# RK3399-AP register map
File version: 1
CPU: CA7 r0p1, little endian, MPU, FPU, I-cache, D-cache, VTOR, 4 interrupt priority bits, 0 interrupts
Registers are 32-bit, read-write, reset 0x0 unless marked. A register's access mark holds for its fields unless they carry their own. Offsets are from the block's base; [hi:lo] are bit positions; <NAME> marks a mode.

## SDMMC
Base 0xFE320000
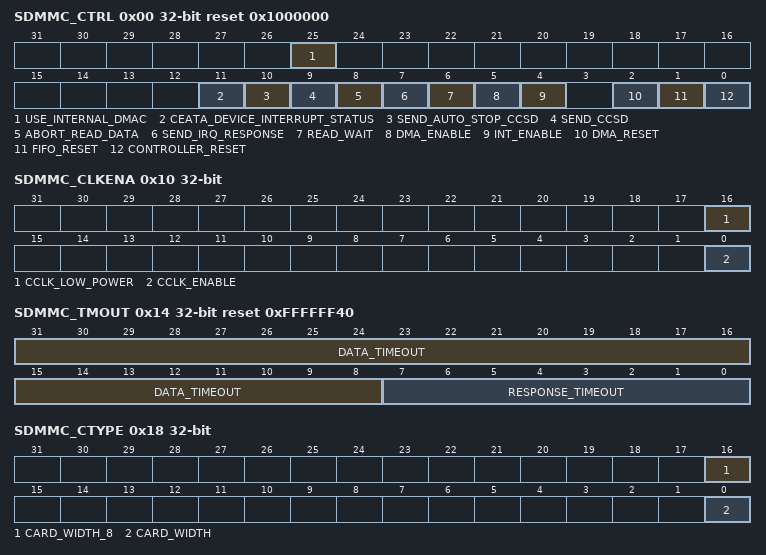
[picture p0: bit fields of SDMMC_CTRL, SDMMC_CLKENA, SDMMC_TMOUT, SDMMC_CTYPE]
0x00 SDMMC_CTRL reset 0x1000000 — Control register
  [25] USE_INTERNAL_DMAC — Present only for the Internal DMAC configuration; else, it is reserved. 0: The host performs data transfers through the slave interface 1: Internal DMAC used for data transfe
  [11] CEATA_DEVICE_INTERRUPT_STATUS — 0: Interrupts not enabled in CE-ATA device (nIEN = 1 in ATA control register) 1: Interrupts are enabled in CE-ATA device (nIEN = 0 in ATA control register) Software should appropriately write to this bit after power-on reset or any other reset to CE-ATA device. After reset, usually CE-ATA device interrupt is disabled (nIEN = 1). If the host enables CE-ATA device interrupt, then software should set this bit.
  [10] SEND_AUTO_STOP_CCSD — 0: Clear bit if Mobile Storage Host Controller does not reset the bit. 1: Send internally generated STOP after sending CCSD to CE-ATA device. NOTE: Always set send_auto_stop_ccsd and send_ccsd bits together send_auto_stop_ccsd should not be set independent of send_ccsd. When set, Mobile Storage Host Controller automatically sends internally- generated STOP command (CMD12) to CE-ATA device. After sending internally-generated STOP command, Auto Command Done (ACD) in RINTSTS is set and generates interrupt to host if Auto Command Done interrupt is not masked. After sending the CCSD, Mobile Storage Host Controller automatically clears send_auto_stop_ccsd bit.
  [9] SEND_CCSD — 0: Clear bit if Mobile Storage Host Controller does not reset the bit. 1: Send Command Completion Signal Disable (CCSD) to CE-ATA device When set, Mobile Storage Host Controller sends CCSD to CE-ATA device. Software sets this bit only if current command is expecting CCS (that is, RW_BLK) and interrupts are enabled in CE-ATA device. Once the CCSD pattern is sent to device, Mobile Storage Host Controller automatically clears send_ccsd bit. It also sets Command Done (CD) bit in RINTSTS register and generates interrupt to host if Command Done interrupt is not masked. NOTE: Once send_ccsd bit is set, it takes two card clock cycles to drive the CCSD on the CMD line. Due to this, during the boundary conditions it may happen that CCSD is sent to the CE-ATA device, even if the device signalled CCS
  [8] ABORT_READ_DATA — 0: no change 1: after suspend command is issued during read-transfer, software polls card to find when suspend happened. Once suspend occurs, software sets bit to reset data state-machine, which is waiting for next block of data. Bit automatically clears once data state machine resets to idle. Used in SDIO card suspend sequence.
  [7] SEND_IRQ_RESPONSE — 0: no change 1: send auto IRQ response Bit automatically clears once response is sent. To wait for MMC card interrupts, host issues CMD40, and SDMMC Controller waits for interrupt response from MMC card(s). In meantime, if host wants SDMMC Controller to exit waiting for interrupt state, it can set this bit, at which time SDMMC Controller command state-machine sends CMD40 response on bus and returns to idle state.
  [6] READ_WAIT — 0: clear read wait 1: assert read wait For sending read-wait to SDIO cards
  [5] DMA_ENABLE — 0: disable DMA transfer mode 1: enable DMA transfer mode Even when DMA mode is enabled, host can still push/pop data into or from FIFO; this should not happen during the normal operation. If there is simultaneous FIFO access from host/DMA, the data coherency is lost. Also, there is no arbitration inside SDMMC Controller to prioritize simultaneous host/DMA access.
  [4] INT_ENABLE — Global interrupt enable/disable bit: 0: disable interrupts 1: enable interrupts The int port is 1 only when this bit is 1 and one or more unmasked interrupts are set.
  [2] DMA_RESET write-1-clears — 0: no change 1: reset internal DMA interface control logic To reset DMA interface, firmware should set bit to 1. This bit is auto-cleared after two AHB clocks.
  [1] FIFO_RESET write-1-clears — 0: no change 1: reset to data FIFO To reset FIFO pointers To reset FIFO, firmware should set bit to 1. This bit is auto- cleared after completion of reset operation
  [0] CONTROLLER_RESET write-1-clears — 0: no change 1: reset SDMMC controller To reset controller, firmware should set bit to 1. This bit is auto- cleared after two AHB and two cclk_in clock cycles. This resets: a. BIU/CIU interface b. CIU and state machines c. abort_read_data, send_irq_response, and read_wait bits of Control register d. start_cmd bit of Command register Does not affect any registers or DMA interface, or FIFO or host interrupts
0x04 SDMMC_PWREN — Power-enable register
  [0] POWER_ENABLE — Power on/off switch for the card. Once power is turned on, firmware should wait for regulator/switch ramp-up time before trying to initialize card. 0: power off 1: power on Bit values output to card_power_en port.
0x08 SDMMC_CLKDIV — Clock-divider register
  [7:0] CLK_DIVIDER0 — Clock divider-0 value. Clock division is 2*n. For example, value of 0 means divide by 2*0 = 0 (no division, bypass), value of 1 means divide by 2*1 = 2, value of "ff"means divide by 2*255 = 510, and so on
0x0C SDMMC_CLKSRC — SD clock source register
  [1:0] CLK_SOURCE — Clock divider source for up to 16 SD cards supported. Each card has two bits assigned to it. For example, bits[1:0] assigned for card-0, which maps and internally routes clock divider[3:0] outputs to cclk_out[15:0] pins, depending on bit value. 00: Clock divider 0 The cclk_out is always from clock divider 0, and this register is not implemented.
0x10 SDMMC_CLKENA — Clock-enable register
  [16] CCLK_LOW_POWER — Low-power control for SD card clock and MMC card clock supported. 0: non-low-power mode 1: low-power mode; stop clock when card in IDLE (should be normally set to only MMC and SD memory cards; for SDIO cards, if interrupts must be detected, clock should not be stopped).
  [0] CCLK_ENABLE — Clock-enable control for SD card clock and MMC card clock supported. 0: clock disabled 1: clock enabled
0x14 SDMMC_TMOUT reset 0xFFFFFF40 — Time-out register
  [31:8] DATA_TIMEOUT — Value for card Data Read Timeout; same value also used for Data Starvation by Host timeout. Value is in number of card output clocks cclk_out of selected card. Note: The software timer should be used if the timeout value is in the order of 100 ms. In this case, read data timeout interrupt needs to be disabled.
  [7:0] RESPONSE_TIMEOUT — Response timeout value. Value is in number of card output clocks –cclk_out.
0x18 SDMMC_CTYPE — Card-type register
  [16] CARD_WIDTH_8 — Indicates if card is 8-bit: 0: non 8-bit mode 1: 8-bit mode
  [0] CARD_WIDTH — Indicates if card is 1-bit or 4-bit: 0: 1-bit mode 1: 4-bit mode
0x1C SDMMC_BLKSIZ reset 0x200 — Block-size register
  [15:0] BLOCK_SIZE
0x20 SDMMC_BYTCNT reset 0x200 — Byte-count register
  [31:0] BYTE_COUNT — Number of bytes to be transferred; should be integer multiple of Block Size for block transfers. For undefined number of byte transfers, byte count should be set to 0. When byte count is set to 0, it is responsibility of host to explicitly send stop/abort command to terminate data transfer.
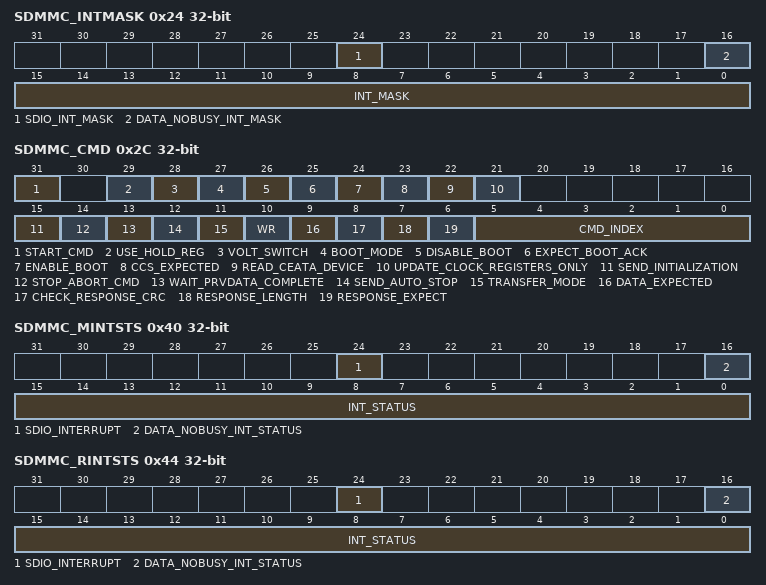
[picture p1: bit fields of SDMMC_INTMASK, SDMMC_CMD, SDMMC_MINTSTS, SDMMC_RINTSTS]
0x24 SDMMC_INTMASK — Interrupt-mask register
  [24] SDIO_INT_MASK — Mask SDIO interrupts. When masked, SDIO interrupt detection for that card is disabled. A 0 masks an interrupt, and 1 enables an interrupt.
  [16] DATA_NOBUSY_INT_MASK — 0: data no busy interrupt not masked 1: data no busy interrupt masked
  [15:0] INT_MASK — Bits used to mask unwanted interrupts. Value of 0 masks interrupt; value of 1 enables interrupt. [15]: End-bit error (read)/Write no CRC (EBE) [14]: Auto command done (ACD) [13]: Start-bit error (SBE) [12]: Hardware locked write error (HLE) [11]: FIFO underrun/overrun error (FRUN) [10]: Data starvation-by-host timeout (HTO) /Volt_switch_int [9]: Data read timeout (DRTO) [8]: Response timeout (RTO) [7]: Data CRC error (DCRC) [6]: Response CRC error (RCRC) [5]: Receive FIFO data request (RXDR) [4]: Transmit FIFO data request (TXDR) [3]: Data transfer over (DTO) [2]: Command done (CD) [1]: Response error (RE) [0]: Card detect (CD)
0x28 SDMMC_CMDARG — Command-argument register
  [31:0] CMD_ARG — Value indicates command argument to be passed to card.
0x2C SDMMC_CMD — Command register
  [31] START_CMD — Start command. Once command is taken by CIU, bit is cleared. When bit is set, host should not attempt to write to any command registers. If write is attempted, hardware lock error is set in raw interrupt register. Once command is sent and response is received from SD_MMC cards, Command Done bit is set in raw interrupt register.
  [29] USE_HOLD_REG — Use Hold Register 0: CMD and DATA sent to card bypassing HOLD Register 1: CMD and DATA sent to card through the HOLD Register Note: a. Set to 1\'b1 for SDR12 and SDR25 (with non-zero phase-shifted cclk_in_drv); zero phase shift is not allowed in these modes. b. Set to 1\'b0 for SDR50, SDR104, and DDR50 (with zero phase- shifted cclk_in_drv). c. Set to 1\'b1 for SDR50, SDR104, and DDR50 (with non-zero phase-shifted cclk_in_drv).
  [28] VOLT_SWITCH — Voltage switch bit. 0: no voltage switching 1: voltage switching enabled; must be set for CMD11 only
  [27] BOOT_MODE — Boot Mode. 0: mandatory Boot operation 1: alternate Boot operation
  [26] DISABLE_BOOT — Disable Boot. When software sets this bit along with start_cmd, CIU terminates the boot operation. Do NOT set disable_boot and enable_boot together.
  [25] EXPECT_BOOT_ACK — Expect Boot Acknowledge. When Software sets this bit along with enable_boot, CIU expects a boot acknowledge start pattern of 0- 1-0 from the selected card.
  [24] ENABLE_BOOT — Enable Boot—this bit should be set only for mandatory boot mode.When Software sets this bit along with start_cmd, CIU starts the boot sequence for the corresponding card by asserting the CMD line low. Do NOT set disable_boot and enable_boot together.
  [23] CCS_EXPECTED — 0: Interrupts are not enabled in CE-ATA device (nIEN = 1 in ATA control register), or command does not expect CCS from device 1: Interrupts are enabled in CE-ATA device (nIEN = 0), and RW_BLK command expects command completion signal from CE- ATA device. If the command expects Command Completion Signal (CCS) from the CE-ATA device, the software should set this control bit. Mobile Storage Host Controller sets Data Transfer Over (DTO) bit in RINTSTS register and generates interrupt to host if Data Transfer Over interrupt is not masked.
  [22] READ_CEATA_DEVICE — 0: Host is not performing read access (RW_REG or RW_BLK) towards CE-ATA device 1: Host is performing read access (RW_REG or RW_BLK) towards CE-ATA device Software should set this bit to indicate that CE-ATA device is being accessed for read transfer. This bit is used to disable read data timeout indication while performing CE-ATA read transfers. Maximum value of I/O transmission delay can be no less than 10 seconds. Mobile Storage Host Controller should not indicate read data timeout while waiting for data from CE-ATA device.
  [21] UPDATE_CLOCK_REGISTERS_ONLY — 0: normal command sequence 1: do not send commands, just update clock register value into card clock domain Following register values transferred into card clock domain: CLKDIV, CLRSRC, CLKENA. Changes card clocks (change frequency, truncate off or on, and set low-frequency mode); provided in order to change clock frequency or stop clock without having to send command to cards. During normal command sequence, when update_clock_registers_only = 0, following control registers are transferred from BIU to CIU: CMD, CMDARG, TMOUT, CTYPE, BLKSIZ, BYTCNT. CIU uses new register values for new command sequence to card. When bit is set, there are no Command Done interrupts because no command is sent to SD_MMC_CEATA cards.
  [15] SEND_INITIALIZATION — 0: do not send initialization sequence (80 clocks of 1) before sending this command 1: send initialization sequence before sending this command After power on, 80 clocks must be sent to card for initialization before sending any commands to card. Bit should be set while sending first command to card so that controller will initialize clocks before sending command to card. This bit should not be set for either of the boot modes (alternate or mandatory).
  [14] STOP_ABORT_CMD — 0: neither stop nor abort command to stop current data transfer in progress. If abort is sent to function-number currently selected or not in data-transfer mode, then bit should be set to 0. 1: stop or abort command intended to stop current data transfer in progress. When open-ended or predefined data transfer is in progress, and host issues stop or abort command to stop data transfer, bit should be set so that command/data state-machines of CIU can return correctly to idle state. This is also applicable for Boot mode transfers. To Abort boot mode, this bit should be set along with CMD[26] = disable_boot.
  [13] WAIT_PRVDATA_COMPLETE — 0: send command at once, even if previous data transfer has not completed 1: wait for previous data transfer completion before sending command The wait_prvdata_complete = 0 option typically used to query status of card during data transfer or to stop current data transfer; card_number should be same as in previous command.
  [12] SEND_AUTO_STOP — 0: no stop command sent at end of data transfer 1: send stop command at end of data transfer When set, SDMMC Controller sends stop command to SD_MMC cards at end of data transfer. a. when send_auto_stop bit should be set, since some data transfers do not need explicit stop commands b. open-ended transfers that software should explicitly send to stop command Additionally, when "resume" is sent to resume –suspended memory access of SD-Combo card –bit should be set correctly if suspended data transfer needs send_auto_stop. Don\'t care if no data expected from card.
  [11] TRANSFER_MODE — 0: block data transfer command 1: stream data transfer command Don\'t care if no data expected.
  [10] WR — 0: read from card 1: write to card Don\'t care if no data expected from card.
  [9] DATA_EXPECTED — 0: no data transfer expected (read/write) 1: data transfer expected (read/write)
  [8] CHECK_RESPONSE_CRC — 0: do not check response CRC 1: check response CRC Some of command responses do not return valid CRC bits. Software should disable CRC checks for those commands in order to disable CRC checking by controller
  [7] RESPONSE_LENGTH — 0: short response expected from card 1: long response expected from card
  [6] RESPONSE_EXPECT — 0: no response expected from card 1: response expected from card
  [5:0] CMD_INDEX — Command index
0x30 SDMMC_RESP0 ro — Response-0 register
  [31:0] RESPONSE0 — Bit[31:0] of response
0x34 SDMMC_RESP1 ro — Response-1 register
  [31:0] RESPONSE — Register represents bit[63:32] of long response. When CIU sends auto-stop command, then response is saved in register. Response for previous command sent by host is still preserved in Response 0 register. Additional auto-stop issued only for data transfer commands, and response type is always "short" for them.
0x38 SDMMC_RESP2 ro — Response-2 register
  [31:0] RESPONSE2 — Bit[95:64] of long response
0x3C SDMMC_RESP3 ro — Response-3 register
  [31:0] RESPONSE3 — Bit[127:96] of long response
0x40 SDMMC_MINTSTS access per field — Masked interrupt-status register
  [24] SDIO_INTERRUPT ro — Interrupt from SDIO card; SDIO interrupt for card enabled only if corresponding sdio_int_mask bit is set in Interrupt mask register (mask bit 1 enables interrupt; 0 masks interrupt). 0: no SDIO interrupt from card 1: SDIO interrupt from card
  [16] DATA_NOBUSY_INT_STATUS rw — Data no busy Interrupt Status
  [15:0] INT_STATUS ro — Interrupt enabled only if corresponding bit in interrupt mask register is set. [15]: End-bit error (read)/Write no CRC (EBE) [14]: Auto command done (ACD) [13]: Start-bit error (SBE) [12]: Hardware locked write error (HLE) [11]: FIFO underrun/overrun error (FRUN) [10]: Data starvation-by-host timeout (HTO) /Volt_switch_int [9]: Data read timeout (DRTO) [8]: Response timeout (RTO) [7]: Data CRC error (DCRC) [6]: Response CRC error (RCRC) [5]: Receive FIFO data request (RXDR) [4]: Transmit FIFO data request (TXDR) [3]: Data transfer over (DTO) [2]: Command done (CD) [1]: Response error (RE) [0]: Card detect (CD)
0x44 SDMMC_RINTSTS access per field — Raw interrupt-status register
  [24] SDIO_INTERRUPT ro — Interrupt from SDIO card; Writes to these bits clear them. Value of 1 clears bit and 0 leaves bit intact. 0: no SDIO interrupt from card 1: SDIO interrupt from card
  [16] DATA_NOBUSY_INT_STATUS rw — Data no busy interrupt status
  [15:0] INT_STATUS ro — Writes to bits clear status bit. Value of 1 clears status bit, and value of 0 leaves bit intact. Bits are logged regardless of interrupt mask status. [15]: End-bit error (read)/Write no CRC (EBE) [14]: Auto command done (ACD) [13]: Start-bit error (SBE) [12]: Hardware locked write error (HLE) [11]: FIFO underrun/overrun error (FRUN) [10]: Data starvation-by-host timeout (HTO) /Volt_switch_int [9]: Data read timeout (DRTO) [8]: Response timeout (RTO) [7]: Data CRC error (DCRC) [6]: Response CRC error (RCRC) [5]: Receive FIFO data request (RXDR) [4]: Transmit FIFO data request (TXDR) [3]: Data transfer over (DTO) [2]: Command done (CD) [1]: Response error (RE) [0]: Card detect (CD)
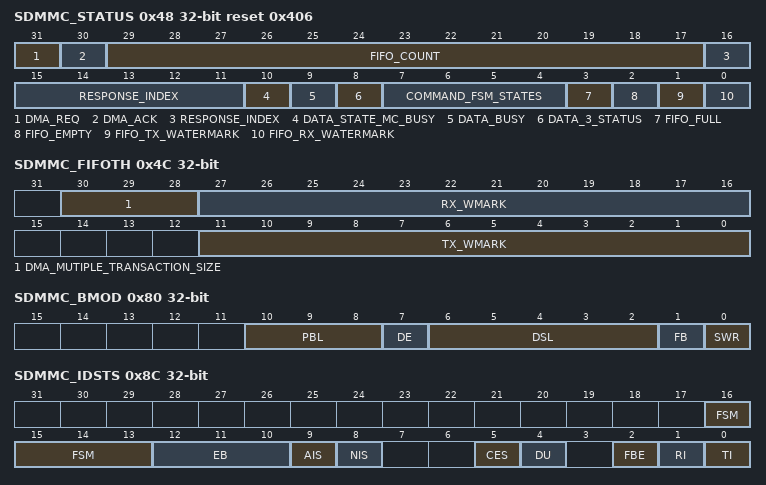
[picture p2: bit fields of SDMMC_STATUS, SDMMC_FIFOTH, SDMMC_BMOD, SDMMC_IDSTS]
0x48 SDMMC_STATUS ro reset 0x406 — Status register
  [31] DMA_REQ — DMA request signal state
  [30] DMA_ACK — DMA acknowledge signal state
  [29:17] FIFO_COUNT — Number of filled locations in FIFO
  [16:11] RESPONSE_INDEX — Index of previous response, including any auto-stop sent by core
  [10] DATA_STATE_MC_BUSY — Data transmit or receive state-machine is busy
  [9] DATA_BUSY — Inverted version of raw selected card_data[0] 0: card data not busy 1: card data busy default value is 1 or 0 depending on cdata_in
  [8] DATA_3_STATUS — Raw selected card_data[3]; checks whether card is present 0: card not present 1: card present default value is 1 or 0 depending on cdata_in
  [7:4] COMMAND_FSM_STATES — Command FSM states: 0: idle 1: send init sequence 2: Tx cmd start bit 3: Tx cmd tx bit 4: Tx cmd index + arg 5: Tx cmd crc7 6: Tx cmd end bit 7: Rx resp start bit 8: Rx resp IRQ response 9: Rx resp tx bit 10: Rx resp cmd idx 11: Rx resp data 12: Rx resp crc7 13: Rx resp end bit 14: Cmd path wait NCC 15: Wait; CMD-to-response turnaround The command FSM state is represented using 19 bits. The STATUS Register[7:4] has 4 bits to represent the command FSM states. Using these 4 bits, only 16 states can be represented. Thus three states cannot be represented in the STATUS[7:4] register. The three states that are not represented in the STATUS Register[7:4] are: a. Bit 16 –Wait for CCS b. Bit 17 –Send CCSD c. Bit 18 –Boot Mode Due to this, while command FSM is in "Wait for CCS state" or "Send CCSD" or "Boot Mode", the Status register indicates status as 0 for the bit field [7:4].
  [3] FIFO_FULL — FIFO is full status
  [2] FIFO_EMPTY — FIFO is empty status
  [1] FIFO_TX_WATERMARK — FIFO reached Transmit watermark level; not qualified with data transfer
  [0] FIFO_RX_WATERMARK — FIFO reached Receive watermark level; not qualified with data transfer
0x4C SDMMC_FIFOTH — FIFO threshold register
  [30:28] DMA_MUTIPLE_TRANSACTION_SIZE — Burst size of multiple transaction; should be programmed same as DMA controller multiple-transaction-size SRC/DEST_MSIZE. 0: 1 transfers 1: 4 2: 8 3: 16 4: 32 5: 64 6: 128 7: 256 The unit for transfer is the H_DATA_WIDTH parameter. A single transfer (dw_dma_single assertion in case of Non DW DMA interface) would be signalled based on this value. Value should be sub-multiple of (RX_WMark + 1)* (F_DATA_WIDTH/H_DATA_WIDTH) and (FIFO_DEPTH - TX_WMark)* (F_DATA_WIDTH/ H_DATA_WIDTH) For example, if FIFO_DEPTH = 16, FDATA_WIDTH == H_DATA_WIDTH Allowed combinations for MSize and TX_WMark are: MSize = 1, TX_WMARK = 1-15 MSize = 4, TX_WMark = 8 MSize = 4, TX_WMark = 4 MSize = 4, TX_WMark = 12 MSize = 8, TX_WMark = 8 MSize = 8, TX_WMark = 4 Allowed combinations for MSize and RX_WMark are: MSize = 1, RX_WMARK = 0-14 MSize = 4, RX_WMark = 3 MSize = 4, RX_WMark = 7 MSize = 4, RX_WMark = 11 MSize = 8, RX_WMark = 7 Recommended: MSize = 8, TX_WMark = 8, RX_WMark = 7
  [27:16] RX_WMARK — FIFO threshold watermark level when receiving data to card. When FIFO data count reaches greater than this number, DMA/FIFO request is raised. During end of packet, request is generated regardless of threshold programming in order to complete any remaining data. In non-DMA mode, when receiver FIFO threshold (RXDR) interrupt is enabled, then interrupt is generated instead of DMA request. During end of packet, interrupt is not generated if threshold programming is larger than any remaining data. It is responsibility of host to read remaining bytes on seeing Data Transfer Done interrupt. In DMA mode, at end of packet, even if remaining bytes are less than threshold, DMA request does single transfers to flush out any remaining bytes before Data Transfer Done interrupt is set. 12 bits-1 bit less than FIFO-count of status register, which is 13 bits. Limitation: RX_WMark <= FIFO_DEPTH-2 Recommended: (FIFO_DEPTH/2) - 1; (means greater than (FIFO_DEPTH/2) - 1)
  [11:0] TX_WMARK — FIFO threshold watermark level when transmitting data to card. When FIFO data count is less than or equal to this number, DMA/FIFO request is raised. If Interrupt is enabled, then interrupt occurs. During end of packet, request or interrupt is generated, regardless of threshold programming. In non-DMA mode, when transmit FIFO threshold (TXDR) interrupt is enabled, then interrupt is generated instead of DMA request. During end of packet, on last interrupt, host is responsible for filling FIFO with only required remaining bytes (not before FIFO is full or after CIU completes data transfers, because FIFO may not be empty). In DMA mode, at end of packet, if last transfer is less than burst size, DMA controller does single cycles until required bytes are transferred. 12 bits -1 bit less than FIFO-count of status register, which is 13 bits. Limitation: TX_WMark >= 1; Recommended: FIFO_DEPTH/2; (means less than or equal to FIFO_DEPTH/2)
0x50 SDMMC_CDETECT ro — Card-detect register
  [0] CARD_DETECT_N — Value on card_detect_n input ports; read-only bits. 0 represents presence of card.
0x54 SDMMC_WRTPRT — Write-protect register
  [0] WRITE_PROTECT — Value on card_write_prt input port. 1 represents write protection.
0x5C SDMMC_TCBCNT ro — Transferred CIU card byte count
  [31:0] TRANS_CARD_BYTE_COUNT — Number of bytes transferred by CIU unit to card. In 32-bit or 64-bit AMBA data-bus-width modes, register should be accessed in full to avoid read-coherency problems. In 16-bit AMBA data-bus-width mode, internal 16-bit coherency register is implemented. User should first read lower 16 bits and then higher 16 bits. When reading lower 16 bits, higher 16 bits of counter are stored in temporary register. When higher 16 bits are read, data from temporary register is supplied. Both TCBCNT and TBBCNT share same coherency register. When AREA_OPTIMIZED parameter is 1, register should be read only after data transfer completes; during data transfer, register returns 0.
0x60 SDMMC_TBBCNT ro — Transferred host/DMA to/from BIU-FIFO byte count
  [31:0] TRANS_FIFO_BYTE_COUNT — Number of bytes transferred between Host/DMA memory and BIU FIFO. In 32-bit or 64-bit AMBA data-bus-width modes, register should be accessed in full to avoid read-coherency problems. In 16-bit AMBA data-bus-width mode, internal 16-bit coherency register is implemented. User should first read lower 16 bits and then higher 16 bits. When reading lower 16 bits, higher 16 bits of counter are stored in temporary register. When higher 16 bits are read, data from temporary register is supplied. Both TCBCNT and TBBCNT share same coherency register.
0x64 SDMMC_DEBNCE reset 0xFFFFFF — Card detect debounce register
  [23:0] DEBOUNCE_COUNT — Number of host clocks (clk) used by debounce filter logic; typical debounce time is 5-25 ms.
0x68 SDMMC_USRID reset 0x7967797 — User ID register
  [31:0] USRID — User identification register. The default value is determined by Configuration Value.
0x6C SDMMC_VERID ro reset 0x5342270A — Version ID register
  [31:0] VERID — Version identification register; register value is hard-wired. Can be read by firmware to support different versions of core.
0x70 SDMMC_HCON ro — Hardware configuration register
  [31:0] HCON — Configuration Dependent. Hardware configurations selected by user before synthesizing core. Register values can be used to develop configuration- independent software drivers. [0]: CARD_TYPE 0: MMC_ONLY 1: SD_MMC [5:1]: NUM_CARDS - 1 [6]: H_BUS_TYPE 0: APB 1: AHB [9:7]: H_DATA_WIDTH 0: 16 bits 1: 32 bits 2: 64 bits others: reserved [15:10]: H_ADDR_WIDTH 0 to 7: reserved 8: 9 bits 9: 10 bits … 31: 32 bits 32 to 63: reserved [17:16]: DMA_INTERFACE 0: none 1: DMA 1 2: DMA 2 3: DMA 3 [20:18]: GE_DMA_DATA_WIDTH 0: 16 bits 1: 32 bits 2: 64 bits others: reserved [21]: FIFO_RAM_INSIDE 0: outside 1: inside [22]: IMPLEMENT_HOLD_REG 0: no hold register 1: hold register [23]: SET_CLK_FALSE_PATH 0: no false path 1: false path set [25:24]: NUM_CLK_DIVIDER-1 [26]: AREA_OPTIMIZED 0: no area optimization 1: Area optimization
0x74 SDMMC_UHS_REG — UHS-1 register
  [16] DDR_REG — DDR mode. Determines the voltage fed to the buffers by an external voltage regulator. 0: non-DDR mode 1: DDR mode UHS_REG [16] should be set for card.
0x78 SDMMC_RST_n access not given reset 0x1 — Hardware reset register
0x80 SDMMC_BMOD access per field — Bus mode register
  [10:8] PBL ro — Programmable Burst Length. These bits indicate the maximum number of beats to be performed in one IDMAC transaction. The IDMAC will always attempt to burst as specified in PBL each time it starts a Burst transfer on the host bus. The permissible values are 1, 4, 8, 16, 32, 64, 128 and 256. This value is the mirror of MSIZE of FIFOTH register. In order to change this value, write the required value to FIFOTH register. This is an encode value as follows. 0: 1 transfers 1: 4 transfers 2: 8 transfers 3: 16 transfers 4: 32 transfers 5: 64 transfers 6: 128 transfers 7: 256 transfers Transfer unit is either 16, 32, or 64 bits, based on HDATA_WIDTH. PBL is a read-only value and is applicable only for Data Access; it does not apply to descriptor accesses.
  [7] DE rw — IDMAC Enable. When set, the IDMAC is enabled.
  [6:2] DSL rw — Descriptor Skip Length. Specifies the number of HWord/Word/Dword (depending on 16/32/64-bit bus) to skip between two unchained descriptors. This is applicable only for dual buffer structure.
  [1] FB rw — Fixed Burst. Controls whether the AHB Master interface performs fixed burst transfers or not. When set, the AHB will use only SINGLE, INCR4, INCR8 or INCR16 during start of normal burst transfers. When reset, the AHB will use SINGLE and INCR burst transfer operations.
  [0] SWR rw — Software Reset. When set, the DMA Controller resets all its internal registers. It is automatically cleared after 1 clock cycle.
0x84 SDMMC_PLDMND wo — Poll demand register
  [31:0] PD — Poll Demand. If the OWN bit of a descriptor is not set, the FSM goes to the Suspend state. The host needs to write any value into this register for the IDMAC FSM to resume normal descriptor fetch operation. This is a write only register.
0x88 SDMMC_DBADDR — Descriptor list base address register
  [31:0] SDL — Start of Descriptor List. Contains the base address of the First Descriptor. The LSB bits [0/1/2:0] for 16/32/64-bit bus-width) are ignored and taken as all-zero by the IDMAC internally. Hence these LSB bits are read-only.
0x8C SDMMC_IDSTS access per field — Internal DMAC status register
  [16:13] FSM ro — DMAC FSM present state. 0: DMA_IDLE 1: DMA_SUSPEND 2: DESC_RD 3: DESC_CHK 4: DMA_RD_REQ_WAI 5: DMA_WR_REQ_WAI 6: DMA_RD 7: DMA_WR 8: DESC_CLOSE
  [12:10] EB ro — Error Bits. Indicates the type of error that caused a Bus Error. Valid only with atal Bus Error bit—IDSTS[2] (IDSTS64[2], in case of 64-bit address configuration) set. This field does not generate an interrupt. 1: Host Abort received during transmission 2: Host Abort received during reception Others: Reserved
  [9] AIS rw — Abnormal Interrupt Summary. Logical OR of the following: IDSTS[2] Fatal Bus Interrupt IDSTS[4] DU bit Interrupt Only unmasked bits affect this bit. This is a sticky bit and must be cleared each time a corresponding bit that causes AIS to be set is cleared. Writing a 1 clears this bit.
  [8] NIS rw — Normal Interrupt Summary. Logical OR of the following: IDSTS[0] Transmit Interrupt IDSTS[1] Receive Interrupt Only unmasked bits affect this bit. This is a sticky bit and must be cleared each time a corresponding bit that causes NIS to be set is cleared. Writing a 1 clears this bit.
  [5] CES rw — Card Error Summary. Indicates the status of the transaction to/from the card; also present in RINTSTS. Indicates the logical OR of the following bits: EBE: End Bit Error RTO: Response Timeout/Boot Ack Timeout RCRC: Response CRC SBE: Start Bit Error DRTO: Data Read Timeout/BDS timeout DCRC: Data CRC for Receive RE: Response Error Writing a 1 clears this bit. The abort condition of the IDMAC depends on the setting of this CES bit. If the CES bit is enabled, then the IDMAC aborts on a "response error"; however, it will not abort if the CES bit is cleared.
  [4] DU rw — Descriptor Unavailable Interrupt. This bit is set when the descriptor is unavailable due to OWN bit = 0 (DES0[31] =0). Writing a 1 clears this bit.
  [2] FBE rw — Fatal Bus Error Interrupt. Indicates that a Bus Error occurred (IDSTS[12:10]) (IDSTS64[12:10], in case of 64-bit address configuration). When this bit is set, the DMA disables all its bus accesses. Writing a 1 clears this bit.
  [1] RI rw — Receive Interrupt. Indicates the completion of data reception for a descriptor. Writing a 1 clears this bit.
  [0] TI rw — Transmit Interrupt. Indicates that data transmission is finished for a descriptor. Writing 1 clears this bit.
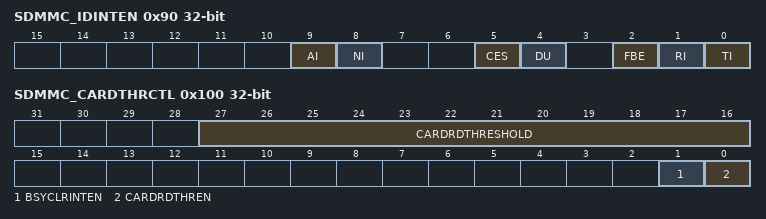
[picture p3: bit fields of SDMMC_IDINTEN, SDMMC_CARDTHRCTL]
0x90 SDMMC_IDINTEN — Internal DMAC interrupt enable register
  [9] AI — Abnormal Interrupt Summary Enable. When set, an abnormal interrupt is enabled. This bit enables the following bits: IDINTEN[ 2] Fatal Bus Error Interrupt IDINTEN[4] DU Interrupt
  [8] NI — Normal Interrupt Summary Enable. When set, a normal interrupt is enabled. When reset, a normal interrupt is disabled. This bit enables the following bits: IDINTEN[0] Transmit Interrupt IDINTEN[1] Receive Interrupt
  [5] CES — Card Error summary Interrupt Enable. When set, it enables the Card Interrupt summary.
  [4] DU — Descriptor Unavailable Interrupt. When set along with Abnormal Interrupt Summary Enable, the DU interrupt is enabled.
  [2] FBE — Fatal Bus Error Enable. When set with Abnormal Interrupt Summary Enable, the Fatal Bus Error Interrupt is enabled. When reset, Fatal Bus Error Enable Interrupt is disabled.
  [1] RI — Receive Interrupt Enable. When set with Normal Interrupt Summary Enable, Receive Interrupt is enabled. When reset, Receive Interrupt is disabled.
  [0] TI — Transmit Interrupt Enable. When set with Normal Interrupt Summary Enable, Transmit Interrupt is enabled. When reset, Transmit Interrupt is disabled.
0x94 SDMMC_DSCADDR — Current host descriptor address register
  [31:0] HDA — Host Descriptor Address Pointer. Cleared on reset. Pointer updated by IDMAC during operation. This register points to the start address of the current descriptor read by the IDMAC.
0x98 SDMMC_BUFADDR — Current buffer descriptor address register
  [31:0] HBA — Host Buffer Address Pointer. Cleared on Reset. Pointer updated by IDMAC during operation. This register points to the current Data Buffer Address being accessed by the IDMAC.
0x100 SDMMC_CARDTHRCTL — Card read threshold enable register
  [27:16] CARDRDTHRESHOLD — Card Read Threshold size
  [1] BSYCLRINTEN — Busy Clear Interrupt generation: 0: Busy Clear Interrupt disabled 1: Busy Clear Interrupt enabled Note: The application can disable this feature if it does not want to wait for a Busy Clear Interrupt. For example, in a multi-card scenario, the application can switch to the other card without waiting for a busy to be completed. In such cases, the application can use the polling method to determine the status of busy. By default this feature is disabled and backward-compatible to the legacy drivers where polling is used.
  [0] CARDRDTHREN — Card Read Threshold Enable. 0: Card Read Threshold disabled 1: Card Read Threshold enabled. Host Controller initiates Read Transfer only if CardRdThreshold amount of space is available in receive FIFO.
0x104 SDMMC_BACK_END_POWER — Back-end power register
  [0] BACK_END_POWER — Back end power 0: Off; Reset 1: Back-end Power supplied to card application
0x10C SDMMC_EMMC_DDR_REG — eMMC4.5 DDR start bit detection control register
  [0] HALF_START_BIT — Control for start bit detection mechanism inside Mobile Storage Host Controller based on duration of start bit; each bit refers to one slot. For eMMC 4.5, start bit can be: 0: Full cycle (HALF_START_BIT = 0) 1: Less than one full cycle (HALF_START_BIT = 1) Set HALF_START_BIT=1 for eMMC 4.5 and above; set to 0 for SD applications.
0x200 SDMMC_FIFO_BASE — FIFO base address register
  [31:0] FIFO_BASE_ADDR — FIFO base address
